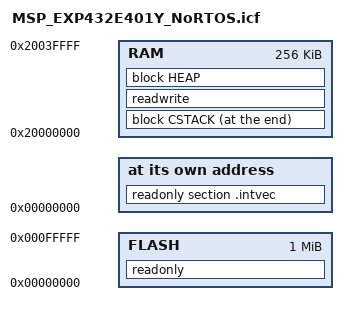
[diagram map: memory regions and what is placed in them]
/*
 * Copyright (c) 2017, Texas Instruments Incorporated
 * All rights reserved.
 *
 * Redistribution and use in source and binary forms, with or without
 * modification, are permitted provided that the following conditions
 * are met:
 *
 * *  Redistributions of source code must retain the above copyright
 *    notice, this list of conditions and the following disclaimer.
 *
 * *  Redistributions in binary form must reproduce the above copyright
 *    notice, this list of conditions and the following disclaimer in the
 *    documentation and/or other materials provided with the distribution.
 *
 * *  Neither the name of Texas Instruments Incorporated nor the names of
 *    its contributors may be used to endorse or promote products derived
 *    from this software without specific prior written permission.
 *
 * THIS SOFTWARE IS PROVIDED BY THE COPYRIGHT HOLDERS AND CONTRIBUTORS "AS IS"
 * AND ANY EXPRESS OR IMPLIED WARRANTIES, INCLUDING, BUT NOT LIMITED TO,
 * THE IMPLIED WARRANTIES OF MERCHANTABILITY AND FITNESS FOR A PARTICULAR
 * PURPOSE ARE DISCLAIMED. IN NO EVENT SHALL THE COPYRIGHT OWNER OR
 * CONTRIBUTORS BE LIABLE FOR ANY DIRECT, INDIRECT, INCIDENTAL, SPECIAL,
 * EXEMPLARY, OR CONSEQUENTIAL DAMAGES (INCLUDING, BUT NOT LIMITED TO,
 * PROCUREMENT OF SUBSTITUTE GOODS OR SERVICES; LOSS OF USE, DATA, OR PROFITS;
 * OR BUSINESS INTERRUPTION) HOWEVER CAUSED AND ON ANY THEORY OF LIABILITY,
 * WHETHER IN CONTRACT, STRICT LIABILITY, OR TORT (INCLUDING NEGLIGENCE OR
 * OTHERWISE) ARISING IN ANY WAY OUT OF THE USE OF THIS SOFTWARE,
 * EVEN IF ADVISED OF THE POSSIBILITY OF SUCH DAMAGE.
 */

define symbol intvec_start__ = 0x00000000;
/*-Memory Regions-*/
define symbol FLASH_start__   = 0x00000000;
define symbol FLASH_end__     = 0x000FFFFF;
define symbol RAM_start__   = 0x20000000;
define symbol RAM_end__     = 0x2003FFFF;
/*-Sizes-*/
define symbol size_cstack__   = 0x1000;
define symbol size_heap__     = 0x2000;

define memory mem with size = 4G;
define region FLASH = mem:[from FLASH_start__   to FLASH_end__];
define region RAM   = mem:[from RAM_start__   to RAM_end__];

define block HEAP      with alignment = 8, size = size_heap__     { };
define block CSTACK    with alignment = 8, size = size_cstack__   { section .stack };
do not initialize { section .stack};
place at end of RAM { block CSTACK };

/* Export stack top symbol. Used by startup file */
define exported symbol STACK_TOP = RAM_end__ + 1;

initialize by copy { readwrite };
do not initialize  { section .noinit };

place at address mem:intvec_start__ { readonly section .intvec };
place in FLASH   { readonly };
place in RAM   { readwrite,
                        block HEAP };
